# CY8C5888LTQ_LP097 register map
File version: 0.1
Registers are 8-bit, read-write, no defined reset value unless marked. A register's access mark holds for its fields unless they carry their own. Offsets are from the block's base; [hi:lo] are bit positions; {n}, {i} and the like mark numbered series; 'fields as' and 'values as' point back to an identical list.

## USBUART — USBFS
Base 0x00000000
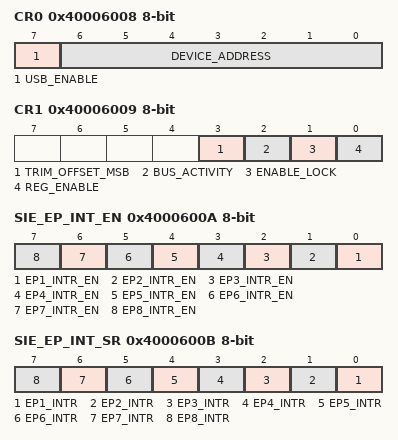
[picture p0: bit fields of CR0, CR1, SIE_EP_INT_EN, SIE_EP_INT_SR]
0x40006008 CR0 — USB Control 0 Register
  [7] USB_ENABLE — This bit enables the device to respond to USB traffic.
    0=Disabled (Block responds to USB traffic.); 1=Enabled (Block does not respond to USB traffic.)
  [6:0] DEVICE_ADDRESS ro — These bits specify the USB device address to which the SIE will respond. This address must be set by firmware and is specified by the USB Host with a SET ADDRESS command during USB enumeration. This value must be programmed by firmware when assigned during enumeration. It is not set automatically by the hardware.
0x40006009 CR1 — USB Control 1 Register
  [3] TRIM_OFFSET_MSB — This bit enables trim bit[7].
  [2] BUS_ACTIVITY — The Bus Activity bit is a stickybit that detects any non-idle USB event that has occurred on the USB bus. Once set to High by the SIE to indicate the bus activity this bit retains its logical High value until firmware clears it.
  [1] ENABLE_LOCK — This bit is set to turn on the automatic frequency locking of the internal oscillator to USB traffic. Unless an external clock is being provided this bit should remain set for proper USB operation.
  [0] REG_ENABLE ro — This bit controls the operation of the internal USB regulator. For applications with supply voltages in the 5V range this bit is set high to enable the internal regulator. For device supply voltage in the 3.3V range this bit is cleared to connect the transceiver directly to the supply.
    0=Disabled (Regulator for 5V is disabled.); 1=Enabled (Regulator for 5V is enabled.)
0x4000600A SIE_EP_INT_EN — USB SIE Data Endpoints Interrupt Enable Register
  [n-1] EP{n}_INTR_EN (n=1..8) — Enables interrupt for EP{n}.
0x4000600B SIE_EP_INT_SR — SIE Data Endpoint Interrupt Status Register
  [n-1] EP{n}_INTR (n=1..8) — Interrupt status for EP{n}.
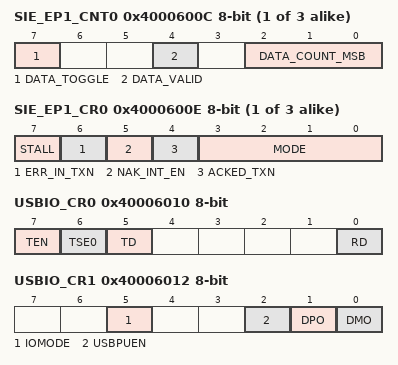
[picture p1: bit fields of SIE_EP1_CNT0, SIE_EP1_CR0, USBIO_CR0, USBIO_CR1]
{0x40005FFC+0x10*i} SIE_EP{i}_CNT0 (i=1..3) — SIE Endpoint 1 Count0 Register
  [7] DATA_TOGGLE — This bit selects the DATA packet's toggle state. For IN transactions firmware must set this bit to the expected state. For OUT transactions the hardware sets this bit to the state of the received Data Toggle bit.
  [4] DATA_VALID — DATA_ERROR - 0, DATA_VALID - 1.
  [2:0] DATA_COUNT_MSB — These bits are the 3 MSb bits of an 11-bit counter. The LSb are the Data Count[7:0] bits of the CNT1 register. Refer to the CNT1 register for more information.
{0x40005FFD+0x10*i} SIE_EP{i}_CNT1 (i=1..3) — SIE Endpoint 1 Count1 Register
  [7:0] DATA_COUNT — These bits are the 8 LSb of a 11-bit counter. The 3 MSb bits are in the CNT0 register. The 11-bit count indicates the number of data bytes in a transaction.
{0x40005FFE+0x10*i} SIE_EP{i}_CR0 (i=1..3) — SIE Endpoint 1 Control Register
  [7] STALL — When this bit is set the SIE stalls an OUT packet if the Mode bits are set to ACK-OUT. The SIE stalls an IN packet if the mode bits are set to ACK-IN. This bit must be clear for all other modes.
  [6] ERR_IN_TXN — The Error in transaction bit is set whenever an error is detected.
  [5] NAK_INT_EN — When set this bit causes an endpoint interrupt to be generated even when a transfer completes with a NAK.
  [4] ACKED_TXN — ACKED_NO - 0, ACKED_YES - 1.
  [3:0] MODE — The mode controls how the USB SIE responds to traffic and how the USB SIE changes the mode of that endpoint as a result of host packets to the endpoint.
    0=DISABLE (Ignore all USB traffic to this endpoint.); 1=NAK_INOUT (SETUP: Accept, IN: NAK, OUT: NAK.); 2=STATUS_OUT_ONLY (SETUP: Accept, IN: STALL, OUT: ACK 0B tokens, NAK others.); 3=STALL_INOUT (SETUP: Accept, IN: STALL, OUT: STALL.); 5=ISO_OUT (SETUP: Ignore, IN: Ignore, OUT: Accept Isochronous OUT token.); 6=STATUS_IN_ONLY (SETUP: Accept, IN: Respond with 0B data, OUT: Stall.); 7=ISO_IN (SETUP: Ignore, IN: Accept Isochronous IN token, OUT: Ignore.); 8=NAK_OUT (SETUP: Ignore, IN: Ignore, OUT: NAK.); 9=ACK_OUT (SETUP: Ignore, IN: Ignore, OUT: Accept data and ACK if STALL = 0, STALL otherwise. Change to MODE=8 after one succesfull OUT token.); 11=ACK_OUT_STATUS_IN (SETUP: Accept, IN: Respond with 0B data, OUT: Accept data.); 12=NAK_IN (SETUP: Ignore, IN: NAK, OUT: Ignore.); 13=ACK_IN (SETUP: Ignore, IN: Respond to IN with data if STALL=0, STALL otherwise, OUT: Ignore); 15=ACK_IN_STATUS_OUT (SETUP: Accept, IN: Respond to IN with data, OUT: ACK 0B tokens, NAK others.)
0x40006010 USBIO_CR0 — USBIO Control 0 Register
  [7] TEN — USB Transmit Enable. This is used to manually transmit on the D+ and D- pins. Normally this bit should be cleared to allow the internal SIE to drive the pins. The most common reason for manually transmitting is to force a resume state on the bus.
  [6] TSE0 — Transmit Single-Ended Zero. SE0: both D+ and D- low. No effect if TEN=0.
  [5] TD — Transmit Data. Transmit a USB J or K state on the USB bus. No effect if TEN=0 or TSE0=1.
    0=DIFF_K (Force USB K state (D+ is low D- is high).); 1=DIFF_J (Force USB J state (D+ is high D- is low).)
  [0] RD ro — Received Data. This read only bit gives the state of the USB differential receiver.
    0=DIFF_LOW (D+ less than D- (K state), or D+=D-=0 (SE0).); 1=DIFF_HIGH (D+ greater than D- (J state).)
0x40006012 USBIO_CR1 — USBIO Control 1 Register
  [5] IOMODE — This bit allows the D+ and D- pins to be configured for either USB mode or bit-banged modes. If this bit is set the DMI and DPI bits are used to drive the D- and D+ pins.
    0=Bit-banged mode for Dm and Dp; 1=USB (USB block controls Dm and Dp.)
  [2] USBPUEN — This bit enables the connection of the internal 1.5 k pull up resistor on the D+ pin.
  [1] DPO ro — This read only bit gives the state of the D+ pin.
  [0] DMO ro — This read only bit gives the state of the D- pin.
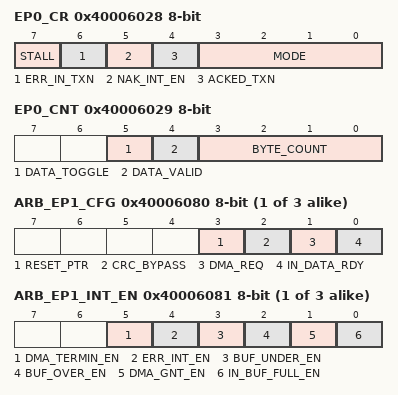
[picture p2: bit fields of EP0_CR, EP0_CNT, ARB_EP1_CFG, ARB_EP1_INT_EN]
0x40006028 EP0_CR — Endpoint0 control Register
  fields as SIE_EP1_CR0
0x40006029 EP0_CNT — Endpoint0 control Register
  [5] DATA_TOGGLE — This bit selects the DATA packet's toggle state. For IN transactions firmware must set this bit to the expected state. For OUT transactions the hardware sets this bit to the state of the received Data Toggle bit.
  [4] DATA_VALID — This bit is used for OUT/SETUP transactions only and is read only. It is cleared to '0' if CRC bit stuffing errors or PID errors occur. This bit does not update for some endpoint mode settings.
    0=DATA_ERROR (No ACK'd transactions since bit was last cleared.); 1=DATA_VALID (Indicates a transaction ended with an ACK.)
  [3:0] BYTE_COUNT — These bits indicate the number of data bytes in a transaction. For IN transactions firmware loads the count with the number of bytes to be transmitted to the host from the endpoint FIFO. Valid values are 0 to 8. For OUT or SETUP transactions the count is updated by hardware to the number of data bytes received plus two for the CRC bytes. Valid values are 2 to 10.
{0x40006070+0x10*i} ARB_EP{i}_CFG (i=1..3) — Arbiter Endpoint 1 Configuration Register
  [3] RESET_PTR — RESET_KRYPTON - 0, RESET_NORMAL - 1
  [2] CRC_BYPASS — CRC_NORMAL - 0, CRC_BYPASS - 1
  [1] DMA_REQ — Manual DMA Request for a particular (1 to 8) endpoint; changing this field from 0 to 1 causes a DMA request to be generated.
  [0] IN_DATA_RDY — Indication that Endpoint Packet Data is Ready in Main memory
{0x40006071+0x10*i} ARB_EP{i}_INT_EN (i=1..3) — Arbiter Endpoint 1 Interrupt Enable Register
  [5] DMA_TERMIN_EN — Endpoint DMA Terminated Enable
  [4] ERR_INT_EN — Endpoint Error in Transaction Interrupt
  [3] BUF_UNDER_EN — Endpoint Buffer Underflow
  [2] BUF_OVER_EN — Endpoint Buffer Overflow
  [1] DMA_GNT_EN — Endpoint DMA Grant
  [0] IN_BUF_FULL_EN — IN Endpoint Local Buffer Full
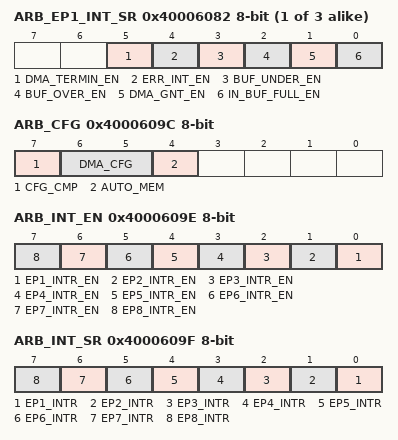
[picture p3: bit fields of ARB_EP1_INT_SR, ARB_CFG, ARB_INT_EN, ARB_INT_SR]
{0x40006072+0x10*i} ARB_EP{i}_INT_SR (i=1..3) — Arbiter Endpoint 1 Interrupt Status Register
  fields as ARB_EP1_INT_EN
{0x40006074+0x10*i} ARB_RW{i}_WA (i=1..3) — Arbiter Endpoint 1 Write Address LSB Register
  [7:0] WA8 — Write Address for EP.
{0x40006075+0x10*i} ARB_RW{i}_WA_MSB (i=1..3) — Arbiter Endpoint 1 Write Address MSB Register
  [0] WA9 — Write Address for EP MSB.
{0x40006076+0x10*i} ARB_RW{i}_RA (i=1..3) — Arbiter Endpoint 1 Read Address LSB Register
  [7:0] RA8 — Read Address for EP MSB.
{0x40006077+0x10*i} ARB_RW{i}_RA_MSB (i=1..3) — Arbiter Endpoint 1 Read Address MSB Register
  [0] RA9 — Read Address for EP MSB.
0x4000609C ARB_CFG — Arbiter configuration register
  [7] CFG_CMP — Register Configuration Complete Indication. Posedge is detected on this bit. Hence a 0 to 1 transition is required.
  [6:5] DMA_CFG — DMA Access Configuration.
    0=DMA_NONE (No DMA.); 1=DMA_MANUAL (Manual DMA.); 2=DMA_AUTO (Auto DMA.)
  [4] AUTO_MEM — Enables Auto Memory Configuration. Manual memory configuration by default.
0x4000609D USB_CLK_EN — USB Control 0 Register
  [7] CSR_CLK_EN — Clock Enable for Core Logic clocked by AHB bus clock.
    0=Disabled (Disables clock to UBS block.); 1=Enabled (Enables clock to UBS block.)
0x4000609E ARB_INT_EN — Arbiter Interrupt Enable Register
  [n-1] EP{n}_INTR_EN (n=1..8) — Enables interrupt for EP{n}.
0x4000609F ARB_INT_SR — Arbiter Interrupt Status
  [n-1] EP{n}_INTR ro (n=1..8) — Interrupt status for EP{n}.

## ENGINE_DECODER
Base 0x00000000
0x4000640E ENGINE_DECODER_Cnt16_COUNTER 16-bit — Counter value
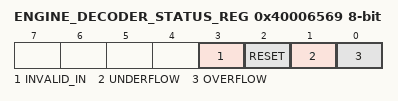
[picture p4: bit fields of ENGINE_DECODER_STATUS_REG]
0x40006569 ENGINE_DECODER_STATUS_REG — Quadrature Decoder Status Register
  [3] INVALID_IN ro — Invalid state transition on the A and B inputs
  [2] RESET ro — Counter Reset due index
  [1] UNDERFLOW ro — Counter underflow
  [0] OVERFLOW ro — Counter overflow

## ENGINE_DECODER_Cnt16
Base 0x00000000; alternate view of ENGINE_DECODER
0x4000640E ENGINE_DECODER_Cnt16_COUNTER 16-bit — UDB.A0 - Current Counter Value
0x4000642E ENGINE_DECODER_Cnt16_PERIOD 16-bit — UDB.D0 - Assigned Period
0x4000643E ENGINE_DECODER_Cnt16_COMPARE 16-bit — UDB.D1 - Assigned Compare Value
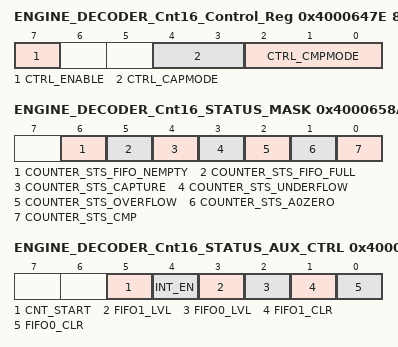
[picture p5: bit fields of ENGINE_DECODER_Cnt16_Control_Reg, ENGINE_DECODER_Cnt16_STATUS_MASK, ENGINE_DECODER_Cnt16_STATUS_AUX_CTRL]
0x4000647E ENGINE_DECODER_Cnt16_Control_Reg — UDB Control Register - Assigned Control Register Value
  [7] CTRL_ENABLE — Enable Counter
  [4:3] CTRL_CAPMODE — Capture mode
  [2:0] CTRL_CMPMODE — Compare mode
0x4000658A ENGINE_DECODER_Cnt16_STATUS_MASK — UDB Status bits Interrupt Mask Enable Register
  [6] COUNTER_STS_FIFO_NEMPTY — FIFO Not Empty Status
  [5] COUNTER_STS_FIFO_FULL — FIFO Full Status
  [4] COUNTER_STS_CAPTURE — Capture Status
  [3] COUNTER_STS_UNDERFLOW — Underflow status
  [2] COUNTER_STS_OVERFLOW — Overflow status
  [1] COUNTER_STS_A0ZERO — A0 Zero ouput status
  [0] COUNTER_STS_CMP — Compare output status
0x4000659A ENGINE_DECODER_Cnt16_STATUS_AUX_CTRL — UDB Auxilliary Control Register
  [5] CNT_START — FIFO0 clear
    0=E_CNT_START0 (Disable counter); 1=E_CNT_START1 (Enable counter)
  [4] INT_EN
    0=E_INT_EN0 (Interrupt disabled); 1=E_INT_EN1 (Interrupt enabled)
  [3] FIFO1_LVL — FIFO level
    0=E_FIFO_LVL_0 (FIFO LVL: input mode: FIFO not full; output mode: FIFO not empty); 1=E_FIFO_LVL_1 (FIFO LVL: input mode: FIFO at least 1/2 empty; output mode: FIFO at least 1/2 full)
  [2] FIFO0_LVL — FIFO level
    values as FIFO1_LVL
  [1] FIFO1_CLR — FIFO1 clear
    0=E_FIFO_CLR_0 (Normal FIFO operation); 1=E_FIFO_CLR_1 (Clear FIFO state)
  [0] FIFO0_CLR — FIFO0 clear
    values as FIFO1_CLR

## UART_PSOC — UART
Base 0x00000000
0x40006427 RX_UART_PSOC_RX_ADDRESS1 — RX Address1 Register
0x40006437 RX_UART_PSOC_RX_ADDRESS2 — RX Address2 Register
0x40006441 TX_UART_PSOC_TX_DATA — TX Data Register
0x40006447 RX_UART_PSOC_RX_DATA — RX Data Register
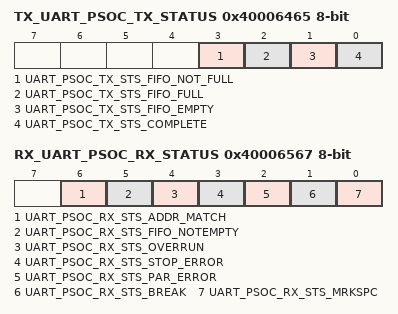
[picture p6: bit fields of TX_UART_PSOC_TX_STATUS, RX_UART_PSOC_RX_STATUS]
0x40006465 TX_UART_PSOC_TX_STATUS — TX status register
  [3] UART_PSOC_TX_STS_FIFO_NOT_FULL ro, [2] UART_PSOC_TX_STS_FIFO_FULL ro, [1] UART_PSOC_TX_STS_FIFO_EMPTY ro, [0] UART_PSOC_TX_STS_COMPLETE ro
0x40006567 RX_UART_PSOC_RX_STATUS — RX status register
  [6] UART_PSOC_RX_STS_ADDR_MATCH ro, [5] UART_PSOC_RX_STS_FIFO_NOTEMPTY ro, [4] UART_PSOC_RX_STS_OVERRUN ro, [3] UART_PSOC_RX_STS_STOP_ERROR ro, [2] UART_PSOC_RX_STS_PAR_ERROR ro, [1] UART_PSOC_RX_STS_BREAK ro, [0] UART_PSOC_RX_STS_MRKSPC ro

## UART_LOG — UART
Base 0x00000000
0x40006428 RX_UART_LOG_RX_ADDRESS1 — RX Address1 Register
0x40006438 RX_UART_LOG_RX_ADDRESS2 — RX Address2 Register
0x40006443 TX_UART_LOG_TX_DATA — TX Data Register
0x40006448 RX_UART_LOG_RX_DATA — RX Data Register
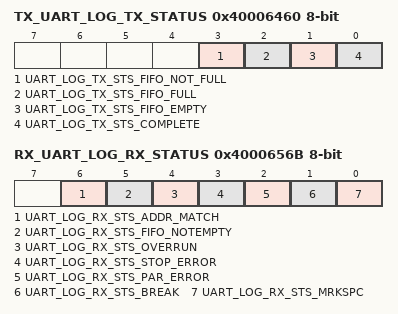
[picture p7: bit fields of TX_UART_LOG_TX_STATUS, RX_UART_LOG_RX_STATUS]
0x40006460 TX_UART_LOG_TX_STATUS — TX status register
  [3] UART_LOG_TX_STS_FIFO_NOT_FULL ro, [2] UART_LOG_TX_STS_FIFO_FULL ro, [1] UART_LOG_TX_STS_FIFO_EMPTY ro, [0] UART_LOG_TX_STS_COMPLETE ro
0x4000656B RX_UART_LOG_RX_STATUS — RX status register
  [6] UART_LOG_RX_STS_ADDR_MATCH ro, [5] UART_LOG_RX_STS_FIFO_NOTEMPTY ro, [4] UART_LOG_RX_STS_OVERRUN ro, [3] UART_LOG_RX_STS_STOP_ERROR ro, [2] UART_LOG_RX_STS_PAR_ERROR ro, [1] UART_LOG_RX_STS_BREAK ro, [0] UART_LOG_RX_STS_MRKSPC ro
